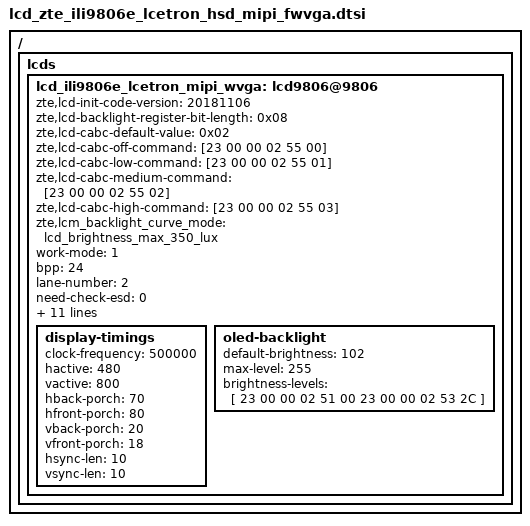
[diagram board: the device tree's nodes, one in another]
/ { lcds {
	lcd_ili9806e_lcetron_mipi_wvga: lcd9806@9806 {
		zte,lcd-init-code-version = "20181106";
		zte,lcd-backlight-register-bit-length = <0x08>;
		zte,lcd-cabc-default-value = <0x02>;
		zte,lcd-cabc-off-command = [23 00 00 02 55 00];
		zte,lcd-cabc-low-command = [23 00 00 02 55 01];
		zte,lcd-cabc-medium-command = [23 00 00 02 55 02];
		zte,lcd-cabc-high-command = [23 00 00 02 55 03];
		zte,lcm_backlight_curve_mode = "lcd_brightness_max_350_lux";

		work-mode = <1>;
		bpp = <24>;
		lane-number = <2>;

		need-check-esd = <0>;
		esd-timeout = <1000>;

		fps = <60>;
		width-mm = <55>;
		height-mm = <94>;
		panel-name = "lcd_ili9806e_lcetron_mipi_wvga";

		power-on-sequence = <
					32  1  5
					32  0  5
					32  1  20
					>;
		power-off-sequence = <
					32  0  20
					>;

		init-data = [
			39 00 00 06 FF FF 98 06 04 01
			39 00 00 02 08 10
			39 00 00 02 21 01
			39 00 00 02 30 02
			39 00 00 02 31 02
			39 00 00 02 40 16
			39 00 00 02 41 33
			39 00 00 02 42 03
			39 00 00 02 43 09
			39 00 00 02 44 09
			39 00 00 02 50 78
			39 00 00 02 51 78
			39 00 00 02 52 00
			39 00 00 02 53 71
			39 00 00 02 54 00
			39 00 00 02 55 83
			39 00 00 02 57 50
			39 00 00 02 60 07
			39 00 00 02 61 00
			39 00 00 02 62 08
			39 00 00 02 63 00

			39 00 00 02 A0 00
			39 00 00 02 A1 05
			39 00 00 02 A2 0E
			39 00 00 02 A3 11
			39 00 00 02 A4 0A
			39 00 00 02 A5 1E
			39 00 00 02 A6 0A
			39 00 00 02 A7 08
			39 00 00 02 A8 04
			39 00 00 02 A9 08
			39 00 00 02 AA 02
			39 00 00 02 AB 06
			39 00 00 02 AC 0A
			39 00 00 02 AD 35
			39 00 00 02 AE 31
			39 00 00 02 AF 00

			39 00 00 02 C0 00
			39 00 00 02 C1 05
			39 00 00 02 C2 0E
			39 00 00 02 C3 0f
			39 00 00 02 C4 09
			39 00 00 02 C5 15
			39 00 00 02 C6 0A
			39 00 00 02 C7 08
			39 00 00 02 C8 03
			39 00 00 02 C9 08
			39 00 00 02 CA 08
			39 00 00 02 CB 05
			39 00 00 02 CC 0C
			39 00 00 02 CD 23
			39 00 00 02 CE 1d
			39 00 00 02 CF 00
			39 00 00 06 FF FF 98 06 04 06
			39 00 00 02 00 21
			39 00 00 02 01 09
			39 00 00 02 02 00
			39 00 00 02 03 00
			39 00 00 02 04 01
			39 00 00 02 05 01
			39 00 00 02 06 80
			39 00 00 02 07 05
			39 00 00 02 08 02
			39 00 00 02 09 80
			39 00 00 02 0A 00
			39 00 00 02 0B 00
			39 00 00 02 0C 0A
			39 00 00 02 0D 0A
			39 00 00 02 0E 00
			39 00 00 02 0F 00
			39 00 00 02 10 E0
			39 00 00 02 11 E4
			39 00 00 02 12 04
			39 00 00 02 13 00
			39 00 00 02 14 00
			39 00 00 02 15 C0
			39 00 00 02 16 08
			39 00 00 02 17 00
			39 00 00 02 18 00
			39 00 00 02 19 00
			39 00 00 02 1A 00
			39 00 00 02 1B 00
			39 00 00 02 1C 00
			39 00 00 02 1D 00
			39 00 00 02 20 01
			39 00 00 02 21 23
			39 00 00 02 22 45
			39 00 00 02 23 67
			39 00 00 02 24 01
			39 00 00 02 25 23
			39 00 00 02 26 45
			39 00 00 02 27 67
			39 00 00 02 30 01
			39 00 00 02 31 11
			39 00 00 02 32 00
			39 00 00 02 33 EE
			39 00 00 02 34 FF
			39 00 00 02 35 CB
			39 00 00 02 36 DA
			39 00 00 02 37 AD
			39 00 00 02 38 BC
			39 00 00 02 39 76
			39 00 00 02 3A 67
			39 00 00 02 3B 22
			39 00 00 02 3C 22
			39 00 00 02 3D 22
			39 00 00 02 3E 22
			39 00 00 02 3F 22
			39 00 00 02 40 22
			39 00 00 02 52 10
			39 00 00 02 53 10
			39 00 00 06 FF FF 98 06 04 07
			39 00 00 02 17 22
			39 00 00 02 02 77

			39 00 00 02 E1 79
			39 00 00 02 26 B2
			39 00 00 06 FF FF 98 06 04 05 // Change to Page 5
			39 00 00 02 00 01
			39 00 00 06 FF FF 98 06 04 00
			39 00 00 02 35 00    //TE=ON
			39 00 00 02 53 2C    //CABC=ON
			39 00 00 02 55 02
			05 78 00 02 11 00
			05 0a 00 02 29 00
			];
		sleep-in = [
			13 0A 00 01 28
			13 78 00 01 10
			];
		sleep-out = [
			13 78 00 01 11
			13 64 00 01 29
			];

		display-timings {
			clock-frequency = <500000>;
			hactive = <480>;
			vactive = <800>;
			hback-porch = <70>;
			hfront-porch = <80>;
			vback-porch = <20>;
			vfront-porch = <18>;
			hsync-len = <10>;
			vsync-len = <10>;
		};
		oled-backlight {
			default-brightness = <102>;
			max-level = <255>;
			brightness-levels = [
				23 00 00 02 51 00
				23 00 00 02 53 2C
			];
		};
	};
};};

